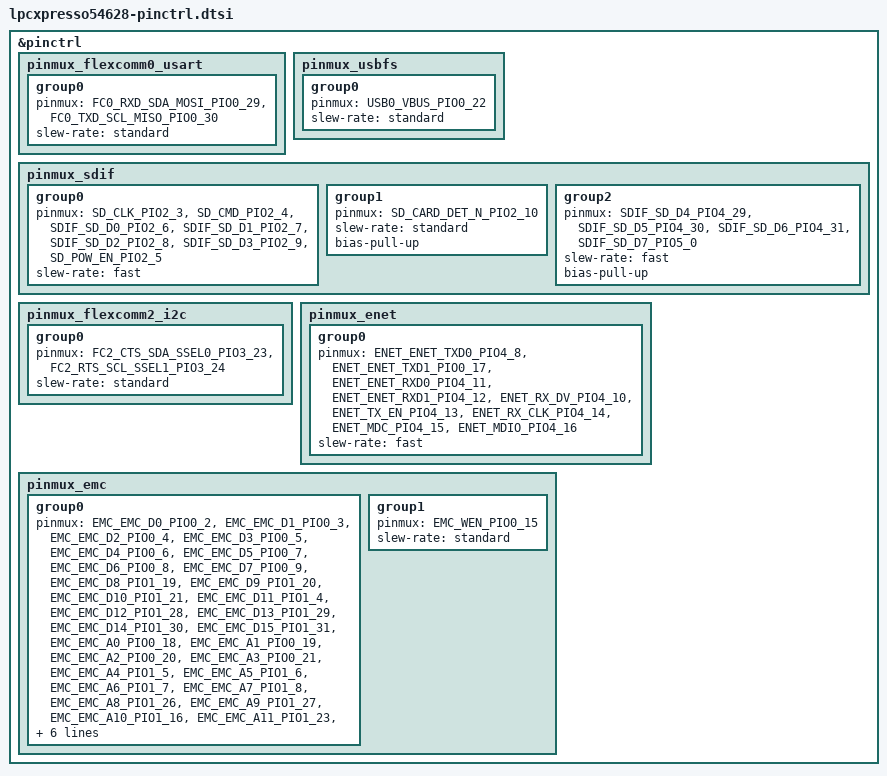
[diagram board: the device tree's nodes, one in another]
/*
 * Copyright 2026 NXP
 *
 * SPDX-License-Identifier: Apache-2.0
 */

#include <nxp/lpc/lpc54xxx/pinctrl/LPC54628J512ET180-pinctrl.h>

/*
 * LPC546xx erratum SDIO.1 requires the four unused upper SD data functions
 * (SD_D4-SD_D7) to be muxed with a pull-up even in 4-bit mode, or SD data
 * transfers fail. This 180-ball package (ET180) does not bond a pad for these
 * signals, so route them to the internal-only pads PIO4_29-31/PIO5_0 - the pads
 * the NXP SDK uses for exactly this - which satisfies the controller without
 * consuming a usable pin. These pads are not in the package pinctrl header (no
 * ball), so their mux values are defined here (IOCON offset = port * 32 + pin,
 * SDIF function = 2).
 */
#define SDIF_SD_D4_PIO4_29 IOCON_MUX(157, IOCON_TYPE_D, 2)
#define SDIF_SD_D5_PIO4_30 IOCON_MUX(158, IOCON_TYPE_D, 2)
#define SDIF_SD_D6_PIO4_31 IOCON_MUX(159, IOCON_TYPE_D, 2)
#define SDIF_SD_D7_PIO5_0  IOCON_MUX(160, IOCON_TYPE_D, 2)

&pinctrl {
	pinmux_flexcomm0_usart: pinmux_flexcomm0_usart {
		group0 {
			pinmux = <FC0_RXD_SDA_MOSI_PIO0_29>,
				 <FC0_TXD_SCL_MISO_PIO0_30>;
			slew-rate = "standard";
		};
	};

	pinmux_usbfs: pinmux_usbfs {
		group0 {
			pinmux = <USB0_VBUS_PIO0_22>;
			slew-rate = "standard";
		};
	};

	/* SD/MMC full-size card slot (J7): 4-bit data + native power-enable. */
	pinmux_sdif: pinmux_sdif {
		group0 {
			pinmux = <SD_CLK_PIO2_3>,
				 <SD_CMD_PIO2_4>,
				 <SDIF_SD_D0_PIO2_6>,
				 <SDIF_SD_D1_PIO2_7>,
				 <SDIF_SD_D2_PIO2_8>,
				 <SDIF_SD_D3_PIO2_9>,
				 <SD_POW_EN_PIO2_5>;
			slew-rate = "fast";
		};

		group1 {
			pinmux = <SD_CARD_DET_N_PIO2_10>;
			slew-rate = "standard";
			bias-pull-up;
		};

		/*
		 * Unused upper data lines, muxed to internal-only pads with
		 * pull-ups to satisfy erratum SDIO.1 (see the note at the top of
		 * this file) without consuming a usable pin.
		 */
		group2 {
			pinmux = <SDIF_SD_D4_PIO4_29>,
				 <SDIF_SD_D5_PIO4_30>,
				 <SDIF_SD_D6_PIO4_31>,
				 <SDIF_SD_D7_PIO5_0>;
			slew-rate = "fast";
			bias-pull-up;
		};
	};

	/* FlexComm2 I2C: the on-board accelerometer (external pull-ups). */
	pinmux_flexcomm2_i2c: pinmux_flexcomm2_i2c {
		group0 {
			pinmux = <FC2_CTS_SDA_SSEL0_PIO3_23>,
				 <FC2_RTS_SCL_SSEL1_PIO3_24>;
			slew-rate = "standard";
		};
	};

	/* RMII Ethernet to the on-board LAN8720A PHY. */
	pinmux_enet: pinmux_enet {
		group0 {
			pinmux = <ENET_ENET_TXD0_PIO4_8>,
				 <ENET_ENET_TXD1_PIO0_17>,
				 <ENET_ENET_RXD0_PIO4_11>,
				 <ENET_ENET_RXD1_PIO4_12>,
				 <ENET_RX_DV_PIO4_10>,
				 <ENET_TX_EN_PIO4_13>,
				 <ENET_RX_CLK_PIO4_14>,
				 <ENET_MDC_PIO4_15>,
				 <ENET_MDIO_PIO4_16>;
			slew-rate = "fast";
		};
	};

	/* EMC: 16-bit data, address, and SDRAM control/strobe/clock lines. */
	pinmux_emc: pinmux_emc {
		group0 {
			pinmux = <EMC_EMC_D0_PIO0_2>,
				 <EMC_EMC_D1_PIO0_3>,
				 <EMC_EMC_D2_PIO0_4>,
				 <EMC_EMC_D3_PIO0_5>,
				 <EMC_EMC_D4_PIO0_6>,
				 <EMC_EMC_D5_PIO0_7>,
				 <EMC_EMC_D6_PIO0_8>,
				 <EMC_EMC_D7_PIO0_9>,
				 <EMC_EMC_D8_PIO1_19>,
				 <EMC_EMC_D9_PIO1_20>,
				 <EMC_EMC_D10_PIO1_21>,
				 <EMC_EMC_D11_PIO1_4>,
				 <EMC_EMC_D12_PIO1_28>,
				 <EMC_EMC_D13_PIO1_29>,
				 <EMC_EMC_D14_PIO1_30>,
				 <EMC_EMC_D15_PIO1_31>,
				 <EMC_EMC_A0_PIO0_18>,
				 <EMC_EMC_A1_PIO0_19>,
				 <EMC_EMC_A2_PIO0_20>,
				 <EMC_EMC_A3_PIO0_21>,
				 <EMC_EMC_A4_PIO1_5>,
				 <EMC_EMC_A5_PIO1_6>,
				 <EMC_EMC_A6_PIO1_7>,
				 <EMC_EMC_A7_PIO1_8>,
				 <EMC_EMC_A8_PIO1_26>,
				 <EMC_EMC_A9_PIO1_27>,
				 <EMC_EMC_A10_PIO1_16>,
				 <EMC_EMC_A11_PIO1_23>,
				 <EMC_EMC_A12_PIO1_24>,
				 <EMC_EMC_A13_PIO1_25>,
				 <EMC_EMC_A14_PIO3_25>,
				 <EMC_CASN_PIO1_9>,
				 <EMC_RASN_PIO1_10>,
				 <EMC_EMC_CLK0_PIO1_11>,
				 <EMC_EMC_DYCS0_PIO1_12>,
				 <EMC_EMC_DQM0_PIO1_13>,
				 <EMC_EMC_DQM1_PIO1_14>,
				 <EMC_EMC_CKE0_PIO1_15>;
			slew-rate = "fast";
		};

		/* Write-enable is driven at standard slew in the reference design. */
		group1 {
			pinmux = <EMC_WEN_PIO0_15>;
			slew-rate = "standard";
		};
	};
};
